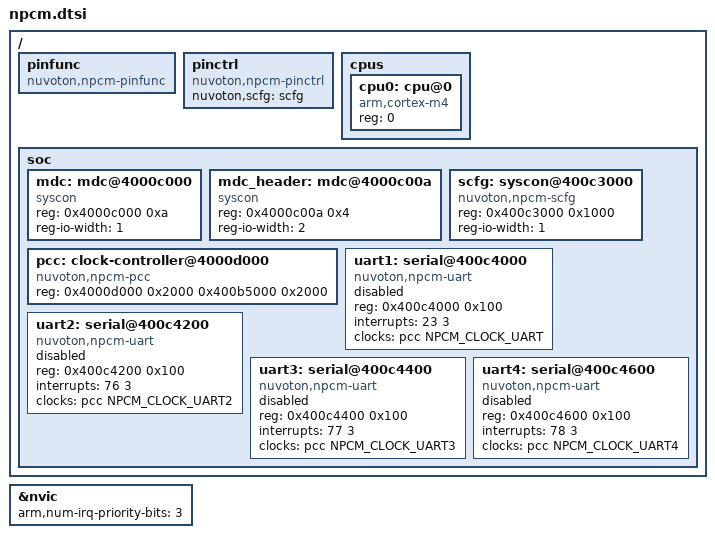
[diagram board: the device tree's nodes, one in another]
/*
 * Copyright (c) 2024 Nuvoton Technology Corporation.
 *
 * SPDX-License-Identifier: Apache-2.0
 */

#include <arm/armv7-m.dtsi>

/* Macros for device tree declarations of npcm soc family */
#include <zephyr/dt-bindings/clock/npcm_clock.h>
#include <freq.h>

/ {
	pinfunc: pinfunc {
		compatible = "nuvoton,npcm-pinfunc";
	};

	pinctrl: pinctrl {
		compatible = "nuvoton,npcm-pinctrl";
		nuvoton,scfg = <&scfg>;
	};

	cpus {
		#address-cells = <1>;
		#size-cells = <0>;

		cpu0: cpu@0 {
			compatible = "arm,cortex-m4";
			reg = <0>;
			device_type = "cpu";
		};
	};

	soc {
		mdc: mdc@4000c000 {
			compatible = "syscon";
			reg = <0x4000c000 0xa>;
			reg-io-width = <1>;
		};

		mdc_header: mdc@4000c00a {
			compatible = "syscon";
			reg = <0x4000c00a 0x4>;
			reg-io-width = <2>;
		};

		pcc: clock-controller@4000d000 {
			compatible = "nuvoton,npcm-pcc";
			/* First reg region is Power Management Controller */
			/* Second reg region is Core Domain Clock Generator */
			reg = <0x4000d000 0x2000
			       0x400b5000 0x2000>;
			/* Cells for clock id */
			#clock-cells = <1>;
			reg-names = "pmc", "cdcg";
		};

		scfg: syscon@400c3000 {
			compatible = "nuvoton,npcm-scfg", "syscon";
			/* System Configuration (SCFG) */
			reg = <0x400c3000 0x1000>;
			reg-io-width = <1>;
		};

		uart1: serial@400c4000 {
			compatible = "nuvoton,npcm-uart";
			reg = <0x400c4000 0x100>;
			interrupts = <23 3>;
			clocks = <&pcc NPCM_CLOCK_UART>;
			status = "disabled";
		};

		uart2: serial@400c4200 {
			compatible = "nuvoton,npcm-uart";
			reg = <0x400c4200 0x100>;
			interrupts = <76 3>;
			clocks = <&pcc NPCM_CLOCK_UART2>;
			status = "disabled";
		};

		uart3: serial@400c4400 {
			compatible = "nuvoton,npcm-uart";
			reg = <0x400c4400 0x100>;
			interrupts = <77 3>;
			clocks = <&pcc NPCM_CLOCK_UART3>;
			status = "disabled";
		};

		uart4: serial@400c4600 {
			compatible = "nuvoton,npcm-uart";
			reg = <0x400c4600 0x100>;
			interrupts = <78 3>;
			clocks = <&pcc NPCM_CLOCK_UART4>;
			status = "disabled";
		};
	};
};

&nvic {
	arm,num-irq-priority-bits = <3>;
};
